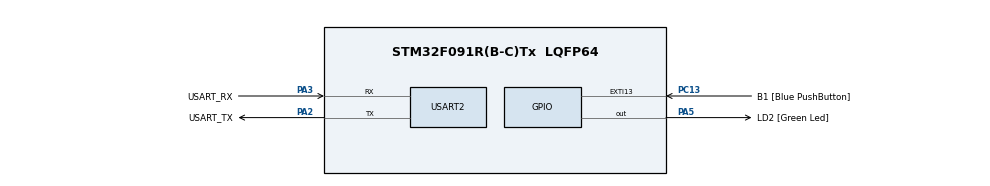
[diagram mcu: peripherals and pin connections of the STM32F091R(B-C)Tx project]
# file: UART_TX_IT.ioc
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Mcu.Family=STM32F0
Mcu.Name=STM32F091R(B-C)Tx
Mcu.Package=LQFP64
NVIC.USART2_IRQn=true\:0\:0\:false\:false\:true\:true
PA13.GPIO_Label=TMS
PA13.Mode=Serial_Wire
PA13.Signal=SYS_SWDIO
PA14.GPIO_Label=TCK
PA14.Mode=Serial_Wire
PA14.Signal=SYS_SWCLK
PA2.GPIO_Label=USART_TX
PA2.GPIO_Mode=GPIO_MODE_AF_PP
PA2.GPIO_PuPd=GPIO_NOPULL
PA2.GPIO_Speed=GPIO_SPEED_FREQ_LOW
PA2.Mode=Asynchronous
PA2.Signal=USART2_TX
PA3.GPIO_Label=USART_RX
PA3.GPIO_Mode=GPIO_MODE_AF_PP
PA3.GPIO_PuPd=GPIO_NOPULL
PA3.GPIO_Speed=GPIO_SPEED_FREQ_LOW
PA3.Mode=Asynchronous
PA3.Signal=USART2_RX
PA5.GPIO_Label=LD2 [Green Led]
PA5.GPIO_Mode=GPIO_MODE_OUTPUT_PP
PA5.GPIO_PuPd=GPIO_NOPULL
PA5.GPIO_Speed=GPIO_SPEED_FREQ_LOW
PA5.Signal=GPIO_Output
PC13.GPIO_Label=B1 [Blue PushButton]
PC13.GPIO_ModeDefaultEXTI=GPIO_MODE_IT_FALLING
PC13.Signal=GPXTI13
PC14OSC32_IN.Mode=LSE-External-Oscillator
PC14OSC32_IN.Signal=RCC_OSC32_IN
PC15OSC32_OUT.Mode=LSE-External-Oscillator
PC15OSC32_OUT.Signal=RCC_OSC32_OUT
PF0-OSC_IN.Mode=HSE-External-Clock-Source
PF0-OSC_IN.Signal=RCC_OSC_IN
PF1-OSC_OUT.Signal=RCC_OSC_OUT
ProjectManager.HeapSize=0x200
ProjectManager.StackSize=0x400
ProjectManager.TargetToolchain=TrueSTUDIO
RCC.AHBFreq_Value=48000000
RCC.APB1Freq_Value=48000000
RCC.APB1TimFreq_Value=48000000
RCC.FLatency-AdvancedSettings=FLASH_LATENCY_1
RCC.HCLKFreq_Value=48000000
RCC.PLLDivider=RCC_PREDIV_DIV2
RCC.PLLMUL=RCC_PLL_MUL12
RCC.PREFETCH_ENABLE-AdvancedSettings=1
RCC.SYSCLKFreq_VALUE=48000000
RCC.SYSCLKSource=RCC_SYSCLKSOURCE_PLLCLK
USART2.OverSampling=UART_OVERSAMPLING_8
USART2.VirtualMode=VM_ASYNC
USART2.VirtualMode-Asynchronous=VM_ASYNC
board=NUCLEO-F091RC

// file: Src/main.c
/**
  ******************************************************************************
  * @file           : main.c
  * @brief          : Main program body
  ******************************************************************************
  ** This notice applies to any and all portions of this file
  * that are not between comment pairs USER CODE BEGIN and
  * USER CODE END. Other portions of this file, whether
  * inserted by the user or by software development tools
  * are owned by their respective copyright owners.
  *
  * COPYRIGHT(c) 2018 STMicroelectronics
  *
  * Redistribution and use in source and binary forms, with or without modification,
  * are permitted provided that the following conditions are met:
  *   1. Redistributions of source code must retain the above copyright notice,
  *      this list of conditions and the following disclaimer.
  *   2. Redistributions in binary form must reproduce the above copyright notice,
  *      this list of conditions and the following disclaimer in the documentation
  *      and/or other materials provided with the distribution.
  *   3. Neither the name of STMicroelectronics nor the names of its contributors
  *      may be used to endorse or promote products derived from this software
  *      without specific prior written permission.
  *
  * THIS SOFTWARE IS PROVIDED BY THE COPYRIGHT HOLDERS AND CONTRIBUTORS "AS IS"
  * AND ANY EXPRESS OR IMPLIED WARRANTIES, INCLUDING, BUT NOT LIMITED TO, THE
  * IMPLIED WARRANTIES OF MERCHANTABILITY AND FITNESS FOR A PARTICULAR PURPOSE ARE
  * DISCLAIMED. IN NO EVENT SHALL THE COPYRIGHT HOLDER OR CONTRIBUTORS BE LIABLE
  * FOR ANY DIRECT, INDIRECT, INCIDENTAL, SPECIAL, EXEMPLARY, OR CONSEQUENTIAL
  * DAMAGES (INCLUDING, BUT NOT LIMITED TO, PROCUREMENT OF SUBSTITUTE GOODS OR
  * SERVICES; LOSS OF USE, DATA, OR PROFITS; OR BUSINESS INTERRUPTION) HOWEVER
  * CAUSED AND ON ANY THEORY OF LIABILITY, WHETHER IN CONTRACT, STRICT LIABILITY,
  * OR TORT (INCLUDING NEGLIGENCE OR OTHERWISE) ARISING IN ANY WAY OUT OF THE USE
  * OF THIS SOFTWARE, EVEN IF ADVISED OF THE POSSIBILITY OF SUCH DAMAGE.
  *
  ******************************************************************************
  */
#include "main.h"

/* USER CODE BEGIN PV */
/* Private variables ---------------------------------------------------------*/

/* USER CODE END PV */

static void LL_Init(void);
void SystemClock_Config(void);
static void MX_GPIO_Init(void);
static void MX_USART2_UART_Init(void);

/* USER CODE BEGIN PFP */
/* Private function prototypes -----------------------------------------------*/
uint8_t data;

/* USER CODE END PFP */
void USART_Rx_Callback(USART_TypeDef *USARTx){
	data = LL_USART_ReceiveData8(USARTx);
}

void UART2_TX_string(char* str){
	while(*str){
		while(!LL_USART_IsActiveFlag_TXE(USART2));
		LL_USART_TransmitData8(USART2, *str);
		str++;
	}
}

void UART2_TX_char(uint8_t str){
	while(!LL_USART_IsActiveFlag_TXE(USART2));
	LL_USART_TransmitData8(USART2, str);
}

int main(void)
{

  /* MCU Configuration----------------------------------------------------------*/

  /* Reset of all peripherals, Initializes the Flash interface and the Systick. */
  LL_Init();

  /* Configure the system clock */
  SystemClock_Config();

  /* Initialize all configured peripherals */
  MX_GPIO_Init();
  MX_USART2_UART_Init();
  /* USER CODE BEGIN 2 */

  LL_USART_EnableIT_RXNE(USART2);

  /* USER CODE END 2 */

  /* Infinite loop */
  /* USER CODE BEGIN WHILE */
  while (1)
  {
	  if(data == 'a'){
		  UART2_TX_string("Hello World! \r\n");
		  data = 0;
	  }
  /* USER CODE END WHILE */

  }

}

static void LL_Init(void)
{

  LL_APB1_GRP2_EnableClock(LL_APB1_GRP2_PERIPH_SYSCFG);
  LL_APB1_GRP1_EnableClock(LL_APB1_GRP1_PERIPH_PWR);

  /* System interrupt init*/
  /* SVC_IRQn interrupt configuration */
  NVIC_SetPriority(SVC_IRQn, 0);
  /* PendSV_IRQn interrupt configuration */
  NVIC_SetPriority(PendSV_IRQn, 0);
  /* SysTick_IRQn interrupt configuration */
  NVIC_SetPriority(SysTick_IRQn, 0);

}

void SystemClock_Config(void)
{

  LL_FLASH_SetLatency(LL_FLASH_LATENCY_1);

  if(LL_FLASH_GetLatency() != LL_FLASH_LATENCY_1)
  {
  Error_Handler();
  }
  LL_RCC_HSI_Enable();

   /* Wait till HSI is ready */
  while(LL_RCC_HSI_IsReady() != 1)
  {

  }
  LL_RCC_HSI_SetCalibTrimming(16);

  LL_RCC_PLL_ConfigDomain_SYS(LL_RCC_PLLSOURCE_HSI, LL_RCC_PLL_MUL_12, LL_RCC_PREDIV_DIV_2);

  LL_RCC_PLL_Enable();

   /* Wait till PLL is ready */
  while(LL_RCC_PLL_IsReady() != 1)
  {

  }
  LL_RCC_SetAHBPrescaler(LL_RCC_SYSCLK_DIV_1);

  LL_RCC_SetAPB1Prescaler(LL_RCC_APB1_DIV_1);

  LL_RCC_SetSysClkSource(LL_RCC_SYS_CLKSOURCE_PLL);

   /* Wait till System clock is ready */
  while(LL_RCC_GetSysClkSource() != LL_RCC_SYS_CLKSOURCE_STATUS_PLL)
  {

  }
  LL_Init1msTick(48000000);

  LL_SYSTICK_SetClkSource(LL_SYSTICK_CLKSOURCE_HCLK);

  LL_SetSystemCoreClock(48000000);

  LL_RCC_SetUSARTClockSource(LL_RCC_USART2_CLKSOURCE_PCLK1);

  /* SysTick_IRQn interrupt configuration */
  NVIC_SetPriority(SysTick_IRQn, 0);
}

/* USART2 init function */
static void MX_USART2_UART_Init(void)
{

  LL_USART_InitTypeDef USART_InitStruct;

  LL_GPIO_InitTypeDef GPIO_InitStruct;

  /* Peripheral clock enable */
  LL_APB1_GRP1_EnableClock(LL_APB1_GRP1_PERIPH_USART2);

  /**USART2 GPIO Configuration
  PA2   ------> USART2_TX
  PA3   ------> USART2_RX
  */
  GPIO_InitStruct.Pin = USART_TX_Pin;
  GPIO_InitStruct.Mode = LL_GPIO_MODE_ALTERNATE;
  GPIO_InitStruct.Speed = LL_GPIO_SPEED_FREQ_LOW;
  GPIO_InitStruct.OutputType = LL_GPIO_OUTPUT_PUSHPULL;
  GPIO_InitStruct.Pull = LL_GPIO_PULL_NO;
  GPIO_InitStruct.Alternate = LL_GPIO_AF_1;
  LL_GPIO_Init(USART_TX_GPIO_Port, &GPIO_InitStruct);

  GPIO_InitStruct.Pin = USART_RX_Pin;
  GPIO_InitStruct.Mode = LL_GPIO_MODE_ALTERNATE;
  GPIO_InitStruct.Speed = LL_GPIO_SPEED_FREQ_LOW;
  GPIO_InitStruct.OutputType = LL_GPIO_OUTPUT_PUSHPULL;
  GPIO_InitStruct.Pull = LL_GPIO_PULL_NO;
  GPIO_InitStruct.Alternate = LL_GPIO_AF_1;
  LL_GPIO_Init(USART_RX_GPIO_Port, &GPIO_InitStruct);

  /* USART2 interrupt Init */
  NVIC_SetPriority(USART2_IRQn, 0);
  NVIC_EnableIRQ(USART2_IRQn);

  USART_InitStruct.BaudRate = 115200;
  USART_InitStruct.DataWidth = LL_USART_DATAWIDTH_8B;
  USART_InitStruct.StopBits = LL_USART_STOPBITS_1;
  USART_InitStruct.Parity = LL_USART_PARITY_NONE;
  USART_InitStruct.TransferDirection = LL_USART_DIRECTION_TX_RX;
  USART_InitStruct.HardwareFlowControl = LL_USART_HWCONTROL_NONE;
  USART_InitStruct.OverSampling = LL_USART_OVERSAMPLING_8;
  LL_USART_Init(USART2, &USART_InitStruct);

  LL_USART_DisableIT_CTS(USART2);

  LL_USART_DisableOverrunDetect(USART2);

  LL_USART_ConfigAsyncMode(USART2);

  LL_USART_Enable(USART2);

}

/** Configure pins as
        * Analog
        * Input
        * Output
        * EVENT_OUT
        * EXTI
*/
static void MX_GPIO_Init(void)
{

  LL_EXTI_InitTypeDef EXTI_InitStruct;
  LL_GPIO_InitTypeDef GPIO_InitStruct;

  /* GPIO Ports Clock Enable */
  LL_AHB1_GRP1_EnableClock(LL_AHB1_GRP1_PERIPH_GPIOC);
  LL_AHB1_GRP1_EnableClock(LL_AHB1_GRP1_PERIPH_GPIOF);
  LL_AHB1_GRP1_EnableClock(LL_AHB1_GRP1_PERIPH_GPIOA);

  /**/
  LL_GPIO_ResetOutputPin(LD2_GPIO_Port, LD2_Pin);

  /**/
  LL_SYSCFG_SetEXTISource(LL_SYSCFG_EXTI_PORTC, LL_SYSCFG_EXTI_LINE13);

  /**/
  LL_GPIO_SetPinPull(B1_GPIO_Port, B1_Pin, LL_GPIO_PULL_NO);

  /**/
  LL_GPIO_SetPinMode(B1_GPIO_Port, B1_Pin, LL_GPIO_MODE_INPUT);

  /**/
  EXTI_InitStruct.Line_0_31 = LL_EXTI_LINE_13;
  EXTI_InitStruct.LineCommand = ENABLE;
  EXTI_InitStruct.Mode = LL_EXTI_MODE_IT;
  EXTI_InitStruct.Trigger = LL_EXTI_TRIGGER_FALLING;
  LL_EXTI_Init(&EXTI_InitStruct);

  /**/
  GPIO_InitStruct.Pin = LD2_Pin;
  GPIO_InitStruct.Mode = LL_GPIO_MODE_OUTPUT;
  GPIO_InitStruct.Speed = LL_GPIO_SPEED_FREQ_LOW;
  GPIO_InitStruct.OutputType = LL_GPIO_OUTPUT_PUSHPULL;
  GPIO_InitStruct.Pull = LL_GPIO_PULL_NO;
  LL_GPIO_Init(LD2_GPIO_Port, &GPIO_InitStruct);

}

void _Error_Handler(char *file, int line)
{
  while(1)
  {
  }
}

/************************ (C) COPYRIGHT STMicroelectronics *****END OF FILE****/
